# FM33G0XX register map
File version: 1.0
CPU: SC000 r1p0, little endian, no MPU, no FPU, 3 interrupt priority bits
Registers are 32-bit, read-write, reset 0x0 unless marked. A register's access mark holds for its fields unless they carry their own. Offsets are from the block's base; [hi:lo] are bit positions; {n}, {i} and the like mark numbered series.

## GPIO_COMMON — GPIO_COMMON Registers
Base 0x40000CE0
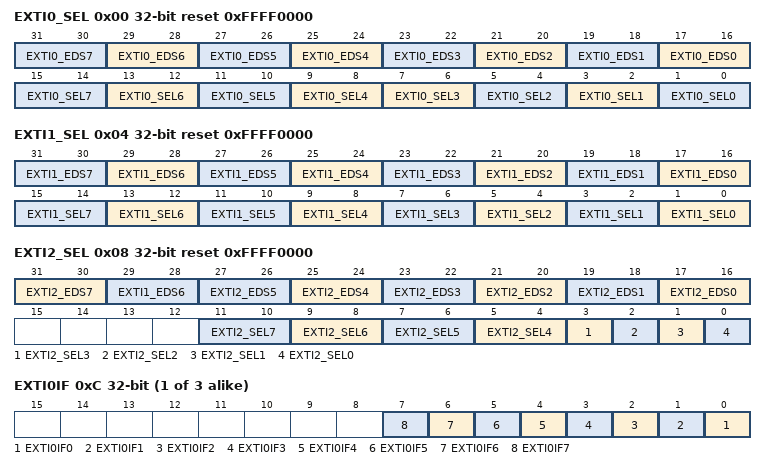
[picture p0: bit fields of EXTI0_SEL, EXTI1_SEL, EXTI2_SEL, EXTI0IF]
0x00 EXTI0_SEL reset 0xFFFF0000 — GPIO EXTI Select 0
  [2n+17:2n+16] EXTI0_EDS{n} (n=0..7) — EXTI0[{n}] trigger edge select
    0=Rising (EXTI0[{n}]); 1=Falling (EXTI0[{n}]); 2=Both (EXTI0[{n}]); 3=Disable (EXTI0[{n}])
  [2n+1:2n] EXTI0_SEL{n} (n=4..7) — EXTI0[{n}] input pin select
    0=PA{n} (EXTI0[{n}]); 1=PA{n+8} (EXTI0[{n}]); 2=PB{n} (EXTI0[{n}]); 3=PB{n+8} (EXTI0[{n}])
  [7:6] EXTI0_SEL3 — EXTI0[3] input pin select
    0=PA3 (EXTI0[3]); 1=PA11 (EXTI0[3]); 2=PB3 (EXTI0[3]); 3=PB10 (EXTI0[3])
  [5:4] EXTI0_SEL2 — EXTI0[2] input pin select
    0=PA2 (EXTI0[2]); 1=PA10 (EXTI0[2]); 2=PB2 (EXTI0[2]); 3=PB10 (EXTI0[2])
  [3:2] EXTI0_SEL1 — EXTI0[1] input pin select
    0=PA1 (EXTI0[1]); 1=PA9 (EXTI0[1]); 2=PB1 (EXTI0[1]); 3=PB9 (EXTI0[1])
  [1:0] EXTI0_SEL0 — EXTI0[0] input pin select
    0=PA0 (EXTI0[0]); 1=PA8 (EXTI0[0]); 2=PB0 (EXTI0[0]); 3=PB8 (EXTI0[0])
0x04 EXTI1_SEL reset 0xFFFF0000 — GPIO EXTI Select 1
  [2n+17:2n+16] EXTI1_EDS{n} (n=0..7) — EXTI1[{n}] trigger edge select
    0=Rising (EXTI1[{n}]); 1=Falling (EXTI1[{n}]); 2=Both (EXTI1[{n}]); 3=Disable (EXTI1[{n}])
  [2n+1:2n] EXTI1_SEL{n} (n=0..7) — EXTI1[{n}] input pin select
    0=PC{n} (EXTI1[{n}]); 1=PC{n+8} (EXTI1[{n}]); 2=PD{n} (EXTI1[{n}]); 3=PD{n+8} (EXTI1[{n}])
0x08 EXTI2_SEL reset 0xFFFF0000 — GPIO EXTI Select 2
  [31:30] EXTI2_EDS7 — EXTI2[7] trigger edge select
    0=Rising (EXTI2[7]); 1=Falling (EXTI2[7]); 2=Both (EXTI2[7]); 3=Disable (EXTI2[7])
  [29:28] EXTI1_EDS6 — EXTI1[6] trigger edge select
    0=Rising (EXTI2[6]); 1=Falling (EXTI2[6]); 2=Both (EXTI2[6]); 3=Disable (EXTI2[6])
  [2n+17:2n+16] EXTI2_EDS{n} (n=0..5) — EXTI2[{n}] trigger edge select
    0=Rising (EXTI2[{n}]); 1=Falling (EXTI2[{n}]); 2=Both (EXTI2[{n}]); 3=Disable (EXTI2[{n}])
  [2n-3:2n-4] EXTI2_SEL{n} (n=4..7) — EXTI2[{n}] input pin select
    0=PE{n+2} (EXTI2[{n}]); 1=PF{n} (EXTI2[{n}]); 2=PF{n+4} (EXTI2[{n}]); 3=PF{n+4} (EXTI2[{n}])
  [3] EXTI2_SEL3 — EXTI2[3] input pin select
    0=PE5 (EXTI2[3]); 1=PF3 (EXTI2[3])
  [2] EXTI2_SEL2 — EXTI2[2] input pin select
    0=PE4 (EXTI2[2]); 1=PF2 (EXTI2[2])
  [1] EXTI2_SEL1 — EXTI2[1] input pin select
    0=PE3 (EXTI2[1]); 1=PF1 (EXTI2[1])
  [0] EXTI2_SEL0 — EXTI2[0] input pin select
    0=PE2 (EXTI2[0]); 1=NULL (EXTI2[0])
{0xC+4i} EXTI{i}IF (i=0..2) — GPIO EXTI interrupt flag {i}
  [n] EXTI{i}IF{n} (n=0..7) — EXTI{i} interrupt flag {n},write 1 to clear
0x18 FOUTSEL — FOUT select
  [3:0] FOUTSEL
    0=XTLF (FOUT select XTLF); 1=RCLP (FOUT select RCLP); 2=RCHF/64 (FOUT select RCHF/64); 3=LSCLK (FOUT select LSCLK); 4=AHBCLK/64 (FOUT select AHBCLK/64); 5=RTCTM (FOUT select RTCTM); 6=PLLO/64 (FOUT select PLLO/64); 7=RTCCLK64Hz (FOUT select RTCCLK64Hz); 8=APBCLK/64 (FOUT select APBCLK/64); 10=LVMOS-Monitor-RCOSC/64 (FOUT select LVMOS-Monitor-RCOSC/64)
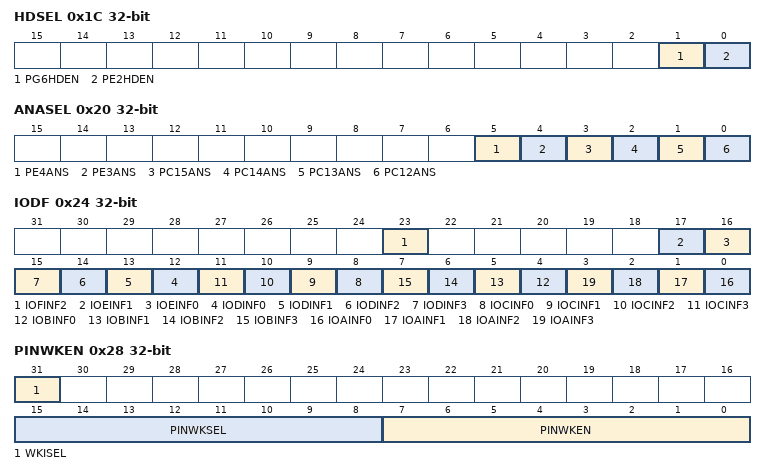
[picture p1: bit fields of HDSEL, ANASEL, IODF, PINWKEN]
0x1C HDSEL — GPIO high drive enable register
  [1] PG6HDEN — PG6 drive enable
  [0] PE2HDEN — PE2 drive enable
0x20 ANASEL — GPIO output data set register
  [5] PE4ANS — PE4 analog function select
    0=ACMP1_INP1; 1=SEG19
  [4] PE3ANS — PE3 analog function select
    0=ACMP1_INN1; 1=SEG18
  [3] PC15ANS — PC15 analog function select
    0=ACMP1_INP0; 1=SEG39
  [2] PC14ANS — PC14 analog function select
    0=ACMP1_INN0; 1=SEG38
  [1] PC13ANS — PC13 analog function select
    0=ADC_IN2; 1=SEG37
  [0] PC12ANS — PC12 analog function select
    0=ADC_IN1; 1=SEG36
0x24 IODF — GPIO digital filter set register
  [23] IOFINF2 — GPIO PF3 digital filter enable
  [17] IOEINF1 — GPIO PE5 digital filter enable
  [16] IOEINF0 — GPIO PE2 digital filter enable
  [n+12] IODINF{n} (n=0..3) — GPIO PD{n} digital filter enable
  [n+8] IOCINF{n} (n=0..3) — GPIO PC{n+12} digital filter enable
  [n+4] IOBINF{n} (n=0..3) — GPIO PB{n+4} digital filter enable
  [n] IOAINF{n} (n=0..3) — GPIO PA{n+8} digital filter enable
0x28 PINWKEN — pin wakeup enable register
  [31] WKISEL — WKUPx INTERUPT ENTRANCE
    0=NMI; 1=N38
  [15:8] PINWKSEL — Portx wakeup edge select, 0-NEG/1-POS
  [7:0] PINWKEN — Portx wakeup enable
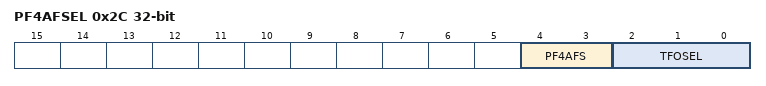
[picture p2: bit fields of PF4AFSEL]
0x2C PF4AFSEL — PF4 Alternate Function Select register
  [4:3] PF4AFS — PF4 Alternate Function Select
    0=UART0_TX; 1=LPUART_TX; 2=TFO; 3=TFO
  [2:0] TFOSEL — Test Freq Output SEL
    0=RCHF; 1=RCHF_4; 2=RCHF_16; 3=PLL; 4=PLL_4; 5=PLL_16; 6=RCLF; 7=RCLP
